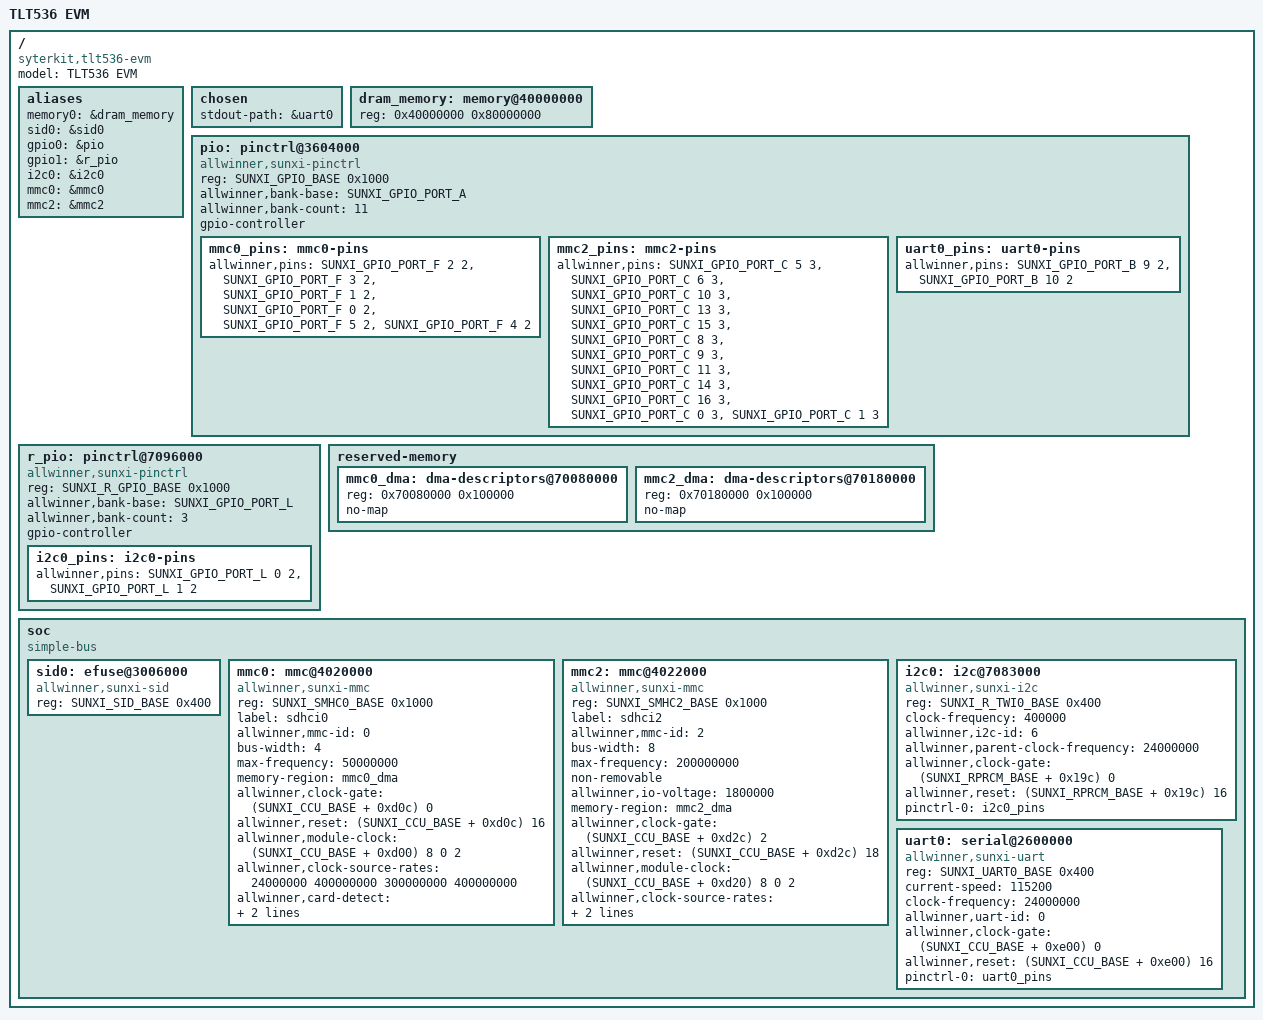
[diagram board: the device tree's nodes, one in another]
// SPDX-License-Identifier: GPL-2.0+
/dts-v1/;

#include <dt-bindings/gpio/sunxi-gpio.h>
#include <dt-bindings/soc/sun55iw6.h>

/ {
	#address-cells = <1>;
	#size-cells = <1>;
	model = "TLT536 EVM";
	compatible = "syterkit,tlt536-evm";

	aliases {
		memory0 = &dram_memory;
		sid0 = &sid0;
		gpio0 = &pio;
		gpio1 = &r_pio;
		i2c0 = &i2c0;
		mmc0 = &mmc0;
		mmc2 = &mmc2;
	};

	chosen {
		stdout-path = &uart0;
	};

	dram_memory: memory@40000000 {
		device_type = "memory";
		reg = <0x40000000 0x80000000>;
	};

	pio: pinctrl@3604000 {
		compatible = "allwinner,sunxi-pinctrl";
		reg = <SUNXI_GPIO_BASE 0x1000>;
		allwinner,bank-base = <SUNXI_GPIO_PORT_A>;
		allwinner,bank-count = <11>;
		gpio-controller;
		#gpio-cells = <3>;

		mmc0_pins: mmc0-pins {
			allwinner,pins =
				<SUNXI_GPIO_PORT_F 2 2>,
				<SUNXI_GPIO_PORT_F 3 2>,
				<SUNXI_GPIO_PORT_F 1 2>,
				<SUNXI_GPIO_PORT_F 0 2>,
				<SUNXI_GPIO_PORT_F 5 2>,
				<SUNXI_GPIO_PORT_F 4 2>;
		};

		mmc2_pins: mmc2-pins {
			allwinner,pins =
				<SUNXI_GPIO_PORT_C 5 3>,
				<SUNXI_GPIO_PORT_C 6 3>,
				<SUNXI_GPIO_PORT_C 10 3>,
				<SUNXI_GPIO_PORT_C 13 3>,
				<SUNXI_GPIO_PORT_C 15 3>,
				<SUNXI_GPIO_PORT_C 8 3>,
				<SUNXI_GPIO_PORT_C 9 3>,
				<SUNXI_GPIO_PORT_C 11 3>,
				<SUNXI_GPIO_PORT_C 14 3>,
				<SUNXI_GPIO_PORT_C 16 3>,
				<SUNXI_GPIO_PORT_C 0 3>,
				<SUNXI_GPIO_PORT_C 1 3>;
		};

		uart0_pins: uart0-pins {
			allwinner,pins =
				<SUNXI_GPIO_PORT_B 9 2>,
				<SUNXI_GPIO_PORT_B 10 2>;
		};
	};

	r_pio: pinctrl@7096000 {
		compatible = "allwinner,sunxi-pinctrl";
		reg = <SUNXI_R_GPIO_BASE 0x1000>;
		allwinner,bank-base = <SUNXI_GPIO_PORT_L>;
		allwinner,bank-count = <3>;
		gpio-controller;
		#gpio-cells = <3>;

		i2c0_pins: i2c0-pins {
			allwinner,pins =
				<SUNXI_GPIO_PORT_L 0 2>,
				<SUNXI_GPIO_PORT_L 1 2>;
		};
	};

	reserved-memory {
		#address-cells = <1>;
		#size-cells = <1>;
		ranges;

		mmc0_dma: dma-descriptors@70080000 {
			reg = <0x70080000 0x100000>;
			no-map;
		};

		mmc2_dma: dma-descriptors@70180000 {
			reg = <0x70180000 0x100000>;
			no-map;
		};
	};

	soc {
		compatible = "simple-bus";
		#address-cells = <1>;
		#size-cells = <1>;
		ranges;

		sid0: efuse@3006000 {
			compatible = "allwinner,sunxi-sid";
			reg = <SUNXI_SID_BASE 0x400>;
			status = "okay";
		};

		mmc0: mmc@4020000 {
			compatible = "allwinner,sunxi-mmc";
			reg = <SUNXI_SMHC0_BASE 0x1000>;
			label = "sdhci0";
			allwinner,mmc-id = <0>;
			bus-width = <4>;
			max-frequency = <50000000>;
			memory-region = <&mmc0_dma>;
			allwinner,clock-gate = <(SUNXI_CCU_BASE + 0xd0c) 0>;
			allwinner,reset = <(SUNXI_CCU_BASE + 0xd0c) 16>;
			allwinner,module-clock =
				<(SUNXI_CCU_BASE + 0xd00) 8 0 2>;
			allwinner,clock-source-rates =
				<24000000 400000000 300000000 400000000>;
			allwinner,card-detect =
				<&pio SUNXI_GPIO_PORT_F 6 0 0>;
			pinctrl-names = "default";
			pinctrl-0 = <&mmc0_pins>;
			status = "okay";
		};

		mmc2: mmc@4022000 {
			compatible = "allwinner,sunxi-mmc";
			reg = <SUNXI_SMHC2_BASE 0x1000>;
			label = "sdhci2";
			allwinner,mmc-id = <2>;
			bus-width = <8>;
			max-frequency = <200000000>;
			non-removable;
			allwinner,io-voltage = <1800000>;
			memory-region = <&mmc2_dma>;
			allwinner,clock-gate = <(SUNXI_CCU_BASE + 0xd2c) 2>;
			allwinner,reset = <(SUNXI_CCU_BASE + 0xd2c) 18>;
			allwinner,module-clock =
				<(SUNXI_CCU_BASE + 0xd20) 8 0 2>;
			allwinner,clock-source-rates =
				<24000000 800000000 600000000 800000000>;
			pinctrl-names = "default";
			pinctrl-0 = <&mmc2_pins>;
			status = "okay";
		};

		i2c0: i2c@7083000 {
			compatible = "allwinner,sunxi-i2c";
			#address-cells = <1>;
			#size-cells = <0>;
			reg = <SUNXI_R_TWI0_BASE 0x400>;
			clock-frequency = <400000>;
			allwinner,i2c-id = <6>;
			allwinner,parent-clock-frequency = <24000000>;
			allwinner,clock-gate = <(SUNXI_RPRCM_BASE + 0x19c) 0>;
			allwinner,reset = <(SUNXI_RPRCM_BASE + 0x19c) 16>;
			pinctrl-names = "default";
			pinctrl-0 = <&i2c0_pins>;
			status = "okay";

		};

		uart0: serial@2600000 {
			compatible = "allwinner,sunxi-uart";
			reg = <SUNXI_UART0_BASE 0x400>;
			current-speed = <115200>;
			clock-frequency = <24000000>;
			allwinner,uart-id = <0>;
			allwinner,clock-gate = <(SUNXI_CCU_BASE + 0xe00) 0>;
			allwinner,reset = <(SUNXI_CCU_BASE + 0xe00) 16>;
			pinctrl-names = "default";
			pinctrl-0 = <&uart0_pins>;
			status = "okay";
		};
	};
};
